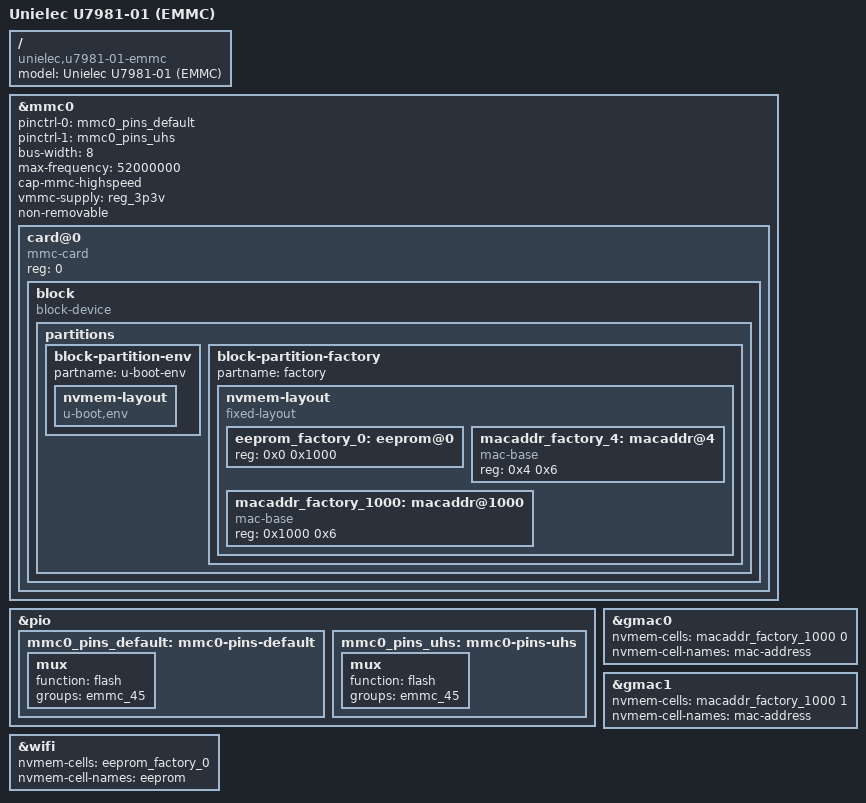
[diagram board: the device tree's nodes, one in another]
// SPDX-License-Identifier: GPL-2.0-or-later OR MIT
/*
 * Copyright (C) 2023 Allen Zhao <allenzhao@unielecinc.com>
 */

/dts-v1/;
#include "mt7981b-unielec-u7981-01.dtsi"
/ {
	model = "Unielec U7981-01 (EMMC)";
	compatible = "unielec,u7981-01-emmc", "mediatek,mt7981";
};

&mmc0 {
	pinctrl-names = "default", "state_uhs";
	pinctrl-0 = <&mmc0_pins_default>;
	pinctrl-1 = <&mmc0_pins_uhs>;
	bus-width = <8>;
	max-frequency = <52000000>;
	cap-mmc-highspeed;
	vmmc-supply = <&reg_3p3v>;
	non-removable;
	status = "okay";

	card@0 {
		compatible = "mmc-card";
		reg = <0>;

		block {
			compatible = "block-device";
			partitions {
				block-partition-env {
					partname = "u-boot-env";

					nvmem-layout {
						compatible = "u-boot,env";
					};
				};

				block-partition-factory {
					partname = "factory";

					nvmem-layout {
						compatible = "fixed-layout";
						#address-cells = <1>;
						#size-cells = <1>;

						eeprom_factory_0: eeprom@0 {
							reg = <0x0 0x1000>;
						};

						macaddr_factory_4: macaddr@4 {
							compatible = "mac-base";
							reg = <0x4 0x6>;
							#nvmem-cell-cells = <1>;
						};

						macaddr_factory_1000: macaddr@1000 {
							compatible = "mac-base";
							reg = <0x1000 0x6>;
							#nvmem-cell-cells = <1>;
						};
					};
				};
			};
		};
	};
};

&pio {
	mmc0_pins_default: mmc0-pins-default {
		mux {
			function = "flash";
			groups = "emmc_45";
		};
	};

	mmc0_pins_uhs: mmc0-pins-uhs {
		mux {
			function = "flash";
			groups = "emmc_45";
		};
	};
};

&gmac0 {
	nvmem-cells = <&macaddr_factory_1000 0>;
	nvmem-cell-names = "mac-address";
};

&gmac1 {
	nvmem-cells = <&macaddr_factory_1000 1>;
	nvmem-cell-names = "mac-address";
};

&wifi {
	nvmem-cells = <&eeprom_factory_0>;
	nvmem-cell-names = "eeprom";
	status = "okay";
};
